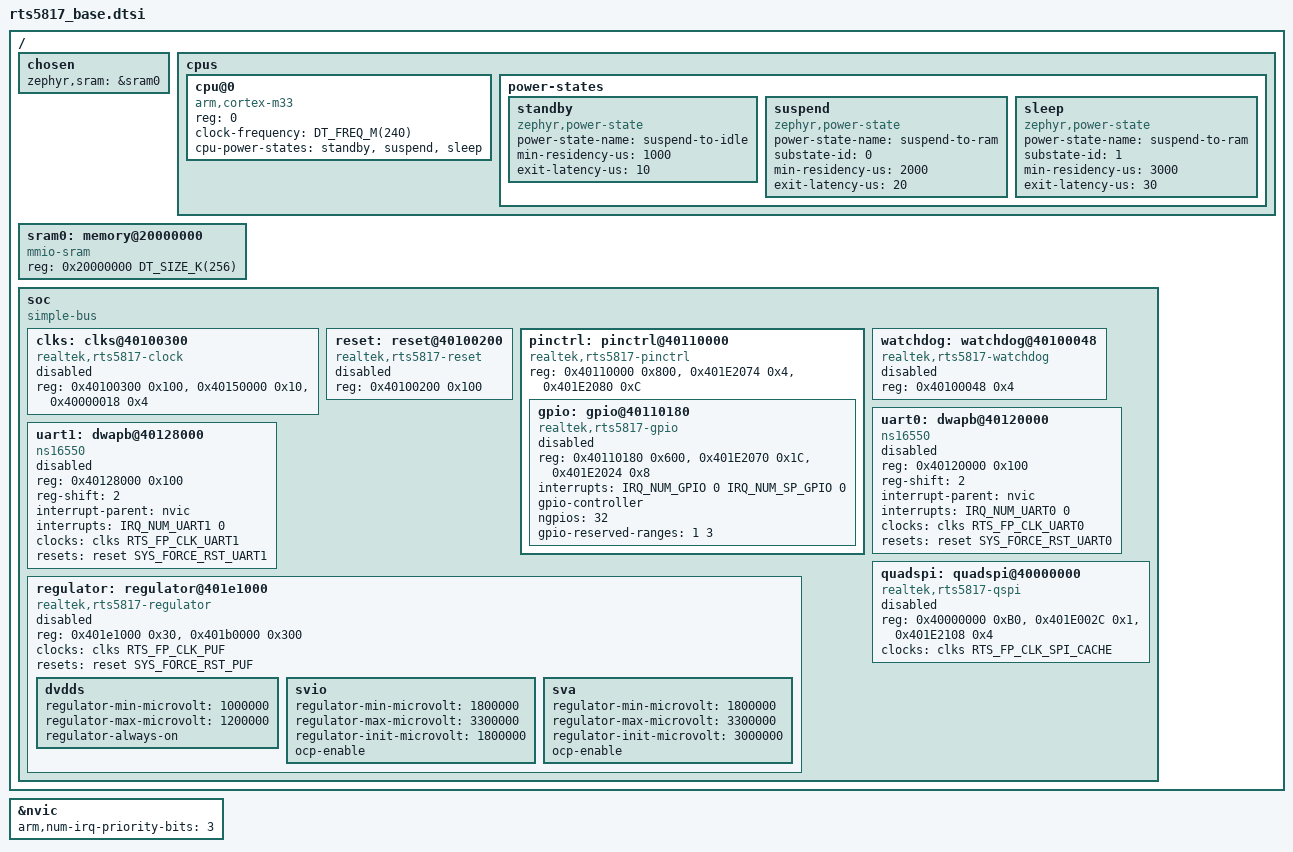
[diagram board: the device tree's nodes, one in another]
/*
 * Copyright (c) 2024 Realtek Semiconductor, Inc.
 * SPDX-License-Identifier: Apache-2.0
 */

#include <arm/armv8-m.dtsi>
#include <mem.h>
#include <freq.h>
#include <zephyr/dt-bindings/interrupt-controller/rts5817_intc.h>
#include <zephyr/dt-bindings/pinctrl/rts5817_pinctrl.h>
#include <zephyr/dt-bindings/reset/rts5817_reset.h>
#include <zephyr/dt-bindings/clock/rts5817_clock.h>
#include <zephyr/dt-bindings/gpio/realtek-rts5817-gpio.h>

/ {
	chosen {
		zephyr,sram = &sram0;
	};

	cpus {
		#address-cells = <1>;
		#size-cells = <0>;

		cpu@0 {
			device_type = "cpu";
			compatible = "arm,cortex-m33";
			reg = <0>;
			clock-frequency = <DT_FREQ_M(240)>;
			#address-cells = <1>;
			#size-cells = <1>;
			cpu-power-states = <&standby &suspend &sleep>;
		};

		power-states {
			standby: standby {
				compatible = "zephyr,power-state";
				power-state-name = "suspend-to-idle";
				min-residency-us = <1000>;
				exit-latency-us = <10>;
			};

			suspend: suspend {
				compatible = "zephyr,power-state";
				power-state-name = "suspend-to-ram";
				substate-id = <0>;
				min-residency-us = <2000>;
				exit-latency-us = <20>;
			};

			sleep: sleep {
				compatible = "zephyr,power-state";
				power-state-name = "suspend-to-ram";
				substate-id = <1>;
				min-residency-us = <3000>;
				exit-latency-us = <30>;
			};
		};
	};

	sram0: memory@20000000 {
		compatible = "mmio-sram";
		reg = <0x20000000 DT_SIZE_K(256)>;
	};

	soc {
		#address-cells = <1>;
		#size-cells = <1>;
		compatible = "simple-bus";

		clks: clks@40100300 {
			compatible = "realtek,rts5817-clock";
			reg = <0x40100300 0x100>,
			      <0x40150000 0x10>,
			      <0x40000018 0x4>;
			#clock-cells = <1>;
			status = "disabled";
		};

		reset: reset@40100200 {
			compatible = "realtek,rts5817-reset";
			reg = <0x40100200 0x100>;
			#reset-cells = <1>;
			status = "disabled";
		};

		pinctrl: pinctrl@40110000 {
			compatible = "realtek,rts5817-pinctrl";
			reg = <0x40110000 0x800>,
			      <0x401E2074 0x4>,
			      <0x401E2080 0xC>;
			#address-cells = <1>;
			#size-cells = <1>;
			status = "okay";

			gpio: gpio@40110180 {
				compatible = "realtek,rts5817-gpio";
				reg = <0x40110180 0x600>,
				      <0x401E2070 0x1C>,
				      <0x401E2024 0x8>;
				interrupts = <IRQ_NUM_GPIO 0 IRQ_NUM_SP_GPIO 0>;
				gpio-controller;
				#gpio-cells = <2>;
				ngpios = <32>;
				gpio-reserved-ranges = <1 3>;
				status = "disabled";
			};
		};

		watchdog: watchdog@40100048 {
			compatible = "realtek,rts5817-watchdog";
			reg = <0x40100048 0x4>;
			status = "disabled";
		};

		uart0: dwapb@40120000 {
			compatible = "ns16550";
			reg = <0x40120000 0x100>;
			reg-shift = <2>;
			interrupt-parent = <&nvic>;
			interrupts = <IRQ_NUM_UART0 0>;
			clocks = <&clks RTS_FP_CLK_UART0>;
			resets = <&reset SYS_FORCE_RST_UART0>;
			status = "disabled";
		};

		uart1: dwapb@40128000 {
			compatible = "ns16550";
			reg = <0x40128000 0x100>;
			reg-shift = <2>;
			interrupt-parent = <&nvic>;
			interrupts = <IRQ_NUM_UART1 0>;
			clocks = <&clks RTS_FP_CLK_UART1>;
			resets = <&reset SYS_FORCE_RST_UART1>;
			status = "disabled";
		};

		quadspi: quadspi@40000000 {
			compatible = "realtek,rts5817-qspi";
			reg = <0x40000000 0xB0>,
			      <0x401E002C 0x1>,
			      <0x401E2108 0x4>;
			clocks = <&clks RTS_FP_CLK_SPI_CACHE>;
			status = "disabled";
		};

		regulator: regulator@401e1000 {
			compatible = "realtek,rts5817-regulator";
			reg = <0x401e1000 0x30>, <0x401b0000 0x300>;
			reg-names = "ctrl", "puf_otp";
			clocks = <&clks RTS_FP_CLK_PUF>;
			resets = <&reset SYS_FORCE_RST_PUF>;
			status = "disabled";
			dvdds {
				regulator-min-microvolt = <1000000>;
				regulator-max-microvolt = <1200000>;
				regulator-always-on;
			};
			svio {
				regulator-min-microvolt = <1800000>;
				regulator-max-microvolt = <3300000>;
				regulator-init-microvolt = <1800000>;
				ocp-enable;
			};
			sva {
				regulator-min-microvolt = <1800000>;
				regulator-max-microvolt = <3300000>;
				regulator-init-microvolt = <3000000>;
				ocp-enable;
			};
		};
	};
};

&nvic {
	arm,num-irq-priority-bits = <3>;
};
